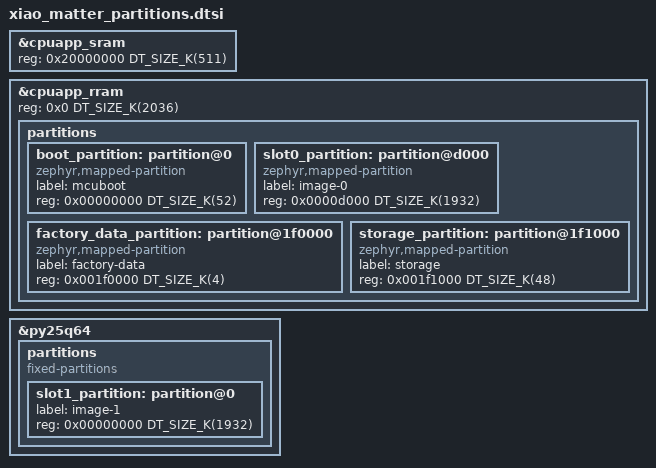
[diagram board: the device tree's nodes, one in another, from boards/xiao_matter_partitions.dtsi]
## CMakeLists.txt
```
#
# Copyright (c) 2021 Nordic Semiconductor ASA
#
# SPDX-License-Identifier: LicenseRef-Nordic-5-Clause
#

cmake_minimum_required(VERSION 3.20.0)

find_package(Zephyr HINTS $ENV{ZEPHYR_BASE})

project(thread-sound-detector)

# Enable GNU STD support.
include(${ZEPHYR_CONNECTEDHOMEIP_MODULE_DIR}/config/nrfconnect/app/enable-gnu-std.cmake)

# NORDIC SDK APP START

# Include all source files that are located in the Matter common directory.
include(${ZEPHYR_NRF_MODULE_DIR}/samples/matter/common/cmake/source_common.cmake)

# Include Data Model utils
include(${ZEPHYR_NRF_MODULE_DIR}/samples/matter/common/cmake/data_model.cmake)

include(${ZEPHYR_NRF_MODULE_DIR}/samples/matter/common/cmake/zap_helpers.cmake)
ncs_get_zap_parent_dir(ZAP_PARENT_DIR)

target_include_directories(app PRIVATE
  src
  ${ZAP_PARENT_DIR}
)

target_sources(app PRIVATE
  src/app_task.cpp
  src/main.cpp
  src/label_provider.cpp
  src/device_info.cpp
  src/audio.c
  src/dsp.c
  src/detector.c
)

if(CONFIG_TSD_MODEL_INT8)
  target_sources(app PRIVATE src/model_q8.c)
endif()

# Inference speed: the rest of the image is size-optimized
set_source_files_properties(src/dsp.c src/model_q8.c PROPERTIES COMPILE_OPTIONS "-O3")

ncs_configure_data_model()
# NORDIC SDK APP END
```

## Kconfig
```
#
# Copyright (c) 2022 Nordic Semiconductor
#
# SPDX-License-Identifier: LicenseRef-Nordic-5-Clause
#
mainmenu "Matter nRF Connect Template Example Application"

# Sample configuration used for Thread networking
if OPENTHREAD

choice OPENTHREAD_NORDIC_LIBRARY_CONFIGURATION
	default OPENTHREAD_NORDIC_LIBRARY_MTD
endchoice

choice OPENTHREAD_DEVICE_TYPE
	default OPENTHREAD_MTD
endchoice

# SED with 0 dBm Thread TX output power for nRF54L15 tag
if BOARD_NRF54L15TAG

config CHIP_ENABLE_ICD_SUPPORT
	default y

config OPENTHREAD_DEFAULT_TX_POWER
	default 0

endif

endif # OPENTHREAD

config CHIP_WIFI
	default y if SHIELD_NRF7002EB2

source "$(ZEPHYR_CONNECTEDHOMEIP_MODULE_DIR)/config/nrfconnect/chip-module/Kconfig.features"
source "$(ZEPHYR_CONNECTEDHOMEIP_MODULE_DIR)/config/nrfconnect/chip-module/Kconfig.defaults"
source "$(ZEPHYR_NRF_MODULE_DIR)/samples/matter/common/src/Kconfig"
config TSD_MODEL_INT8
	bool "Int8 sound model (CMSIS-NN)"
	select CMSIS_NN
	select CMSIS_NN_CONVOLUTION
	select CMSIS_NN_POOLING
	select CMSIS_NN_NNSUPPORT
	help
	  Run the int8 quantised model (model/quantize.py, model_data_q8.h)
	  with CMSIS-NN instead of the float model (model_data.h).

source "Kconfig.zephyr"
```

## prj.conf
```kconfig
#
# Copyright (c) 2021 Nordic Semiconductor ASA
#
# SPDX-License-Identifier: LicenseRef-Nordic-5-Clause
#

# This sample uses Kconfig.defaults to set options common for all
# samples. This file should contain only options specific for this sample
# or overrides of default values.

# Enable CHIP
CONFIG_CHIP=y
CONFIG_CHIP_PROJECT_CONFIG="src/chip_project_config.h"
CONFIG_CHIP_DEVICE_PRODUCT_NAME="Sound Detector"
CONFIG_CHIP_DEVICE_VENDOR_NAME="KinDR Software"

# Configure ZAP file name
CONFIG_NCS_SAMPLE_MATTER_ZAP_FILE_PATH="${APPLICATION_CONFIG_DIR}/src/default_zap/sound_detector.zap"

# 32768 == 0x8000: test product ID; together with test vendor 0xFFF1 Home Assistant
# names entities from the "ha_entitylabel" Fixed Label.
# (example Product ID added temporaly,
# but it must be changed with proper PID from the list:
# https://github.com/project-chip/connectedhomeip/blob/482e6fd03196a6de45465a90003947ef4b86e0b1/docs/examples/discussion/PID_allocation_for_example_apps.md)
CONFIG_CHIP_DEVICE_PRODUCT_ID=32768
CONFIG_STD_CPP17=y

# Enable Matter pairing automatically on application start.
CONFIG_CHIP_ENABLE_PAIRING_AUTOSTART=y

# Enable Matter extended announcement and increase duration to 1 hour.
CONFIG_CHIP_BLE_EXT_ADVERTISING=y
CONFIG_CHIP_BLE_ADVERTISING_DURATION=60

# Add support for LEDs and buttons on Nordic development kits
CONFIG_DK_LIBRARY=y

# Bluetooth Low Energy configuration
CONFIG_BT_DEVICE_NAME="SoundDetector"

# Other settings
CONFIG_THREAD_NAME=y
CONFIG_MPU_STACK_GUARD=y
CONFIG_RESET_ON_FATAL_ERROR=n
CONFIG_CHIP_LIB_SHELL=y
CONFIG_NCS_SAMPLE_MATTER_TEST_SHELL=y

# Disable NFC onboarding
CONFIG_CHIP_NFC_ONBOARDING_PAYLOAD=n

# Reduce application size
CONFIG_USE_SEGGER_RTT=n

# Enable Factory Data feature
CONFIG_CHIP_FACTORY_DATA=y
CONFIG_CHIP_FACTORY_DATA_BUILD=y

# ---- Sound detector ----
CONFIG_AUDIO=y
CONFIG_AUDIO_DMIC=y
CONFIG_FPU=y
CONFIG_CMSIS_DSP=y
CONFIG_CMSIS_DSP_TRANSFORM=y
CONFIG_SHELL=y

# snd selftest runs the CNN in the shell thread (CMSIS-NN needs more stack)
CONFIG_SHELL_STACK_SIZE=4096

# Logging off the hot path: minimal mode printed synchronously over UART in the
# calling thread, Matter debug bursts starved audio capture (PDM overruns ->
# restart transients -> false beep/smoke_alarm events -> more Matter traffic).
CONFIG_LOG_MODE_DEFERRED=y
CONFIG_LOG_BUFFER_SIZE=8192
CONFIG_MATTER_LOG_LEVEL_WRN=y
```

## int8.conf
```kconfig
# Int8 model variant: scripts/fw.sh build with MODEL=int8
CONFIG_TSD_MODEL_INT8=y
```

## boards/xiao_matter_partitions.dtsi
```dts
/*
 * Matter partition layout for XIAO nRF54LM20A, modelled on NCS
 * nrf/dts/samples/matter/nrf54lm20_cpuapp_partitions.dtsi, with the DFU
 * secondary slot in the on-board PY25Q64 external flash (Seeed wiki).
 */

&cpuapp_sram {
	reg = <0x20000000 DT_SIZE_K(511)>;
	ranges = <0x0 0x20000000 DT_SIZE_K(511)>;
};

&cpuapp_rram {
	reg = <0x0 DT_SIZE_K(2036)>;

	/delete-node/ partitions;

	partitions {
		ranges;
		#address-cells = <1>;
		#size-cells = <1>;

		boot_partition: partition@0 {
			compatible = "zephyr,mapped-partition";
			label = "mcuboot";
			reg = <0x00000000 DT_SIZE_K(52)>;
		};

		slot0_partition: partition@d000 {
			compatible = "zephyr,mapped-partition";
			label = "image-0";
			reg = <0x0000d000 DT_SIZE_K(1932)>;
		};

		factory_data_partition: partition@1f0000 {
			compatible = "zephyr,mapped-partition";
			label = "factory-data";
			reg = <0x001f0000 DT_SIZE_K(4)>;
		};

		storage_partition: partition@1f1000 {
			compatible = "zephyr,mapped-partition";
			label = "storage";
			reg = <0x001f1000 DT_SIZE_K(48)>;
		};
	};
};

&py25q64 {
	status = "okay";

	partitions {
		compatible = "fixed-partitions";
		#address-cells = <1>;
		#size-cells = <1>;

		slot1_partition: partition@0 {
			label = "image-1";
			reg = <0x00000000 DT_SIZE_K(1932)>;
		};
	};
};
```

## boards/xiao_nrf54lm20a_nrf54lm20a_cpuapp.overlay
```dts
#include "xiao_matter_partitions.dtsi"

/ {
	aliases {
		watchdog0 = &wdt31;
	};

	chosen {
		nordic,pm-ext-flash = &py25q64;
	};
};

&wdt31 {
	status = "okay";
};

/* Sense variant: PDM microphone, supply (PMIC LDO1) enabled at boot */
dmic_dev: &pdm20 {
	status = "okay";
};

/* As in Seeed's zephyr-dmic example */
&pwm20 {
	status = "disabled";
};
```

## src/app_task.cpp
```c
/*
 * Thread sound detector, Matter over Thread.
 *
 * Every sound class is a Generic Switch endpoint (1..N). A confirmed sound
 * event emits Switch InitialPress on that endpoint, which Home Assistant shows
 * as an event entity named after the class (Fixed Label "ha_entitylabel").
 *
 * Init structure based on the nRF Connect SDK Matter template sample,
 * Copyright (c) 2021 Nordic Semiconductor ASA
 * SPDX-License-Identifier: LicenseRef-Nordic-5-Clause
 */

#include "app_task.h"

#include "app/matter_init.h"
#include "app/task_executor.h"
#include "board/board.h"
#include "clusters/identify.h"
#include "lib/core/CHIPError.h"
#include "lib/support/CodeUtils.h"

#include <app/clusters/switch-server/switch-server.h>
#include <platform/CHIPDeviceLayer.h>
#include <setup_payload/OnboardingCodesUtil.h>

#include <zephyr/logging/log.h>
#include <zephyr/shell/shell.h>

#include <cstdlib>
#include <cstring>
#include <new>

#include "audio.h"
#include "detector.h"
#include "device_info.h"
#include "dsp.h"
#include "label_provider.h"

LOG_MODULE_DECLARE(app, CONFIG_CHIP_APP_LOG_LEVEL);

using namespace ::chip;
using namespace ::chip::app;
using namespace ::chip::DeviceLayer;

namespace {

SoundLabelProvider sLabelProvider;

/* Identify cluster on every sound endpoint (required by the Generic Switch device type). No LED or
 * sound to show, so identify requests are only logged. */
class LogIdentifyDelegate : public Clusters::IdentifyDelegate {
public:
	void OnIdentifyStart(Clusters::IdentifyCluster &) override { LOG_INF("Identify start"); }
	void OnIdentifyStop(Clusters::IdentifyCluster &) override { LOG_INF("Identify stop"); }
	void OnTriggerEffect(Clusters::IdentifyCluster &) override { LOG_INF("Identify trigger effect"); }
	bool IsTriggerEffectEnabled() const override { return false; }
};

LogIdentifyDelegate sIdentifyDelegate;
DefaultTimerDelegate sIdentifyTimer;
alignas(Nrf::Matter::IdentifyCluster) uint8_t sIdentifyStorage[MD_N_CLASSES][sizeof(Nrf::Matter::IdentifyCluster)];

CHIP_ERROR InitIdentify()
{
	for (int i = 0; i < MD_N_CLASSES; i++) {
		auto *cluster = new (sIdentifyStorage[i]) Nrf::Matter::IdentifyCluster(
			SoundLabelProvider::kFirstEndpoint + i, sIdentifyDelegate, sIdentifyTimer,
			Clusters::Identify::IdentifyTypeEnum::kNone);

		ReturnErrorOnFailure(cluster->Init());
	}
	return CHIP_NO_ERROR;
}

/* Runs on the Matter thread. */
void EmitSoundEvent(intptr_t cls)
{
	EndpointId ep = SoundLabelProvider::kFirstEndpoint + static_cast<EndpointId>(cls);

	Clusters::SwitchServer::Instance().OnInitialPress(ep, 1);
	LOG_INF("Matter event: %s on endpoint %u", SoundLabelProvider::PrettyName(cls), ep);
}

/* Called from the inference thread. */
void OnSoundEvent(int cls, float prob)
{
	ARG_UNUSED(prob);
	PlatformMgr().ScheduleWork(EmitSoundEvent, static_cast<intptr_t>(cls));
}

void OnAudioResult(const struct audio_result *res)
{
	detector_feed(res);
}

int CmdSelftest(const struct shell *sh, size_t argc, char **argv)
{
	int64_t t0 = k_uptime_get();
	float diff = dsp_selftest();

	shell_print(sh, "selftest: max |logit diff| vs Python = %.6f (%s), %lld ms", (double)diff,
		    diff < DSP_SELFTEST_TOL ? "PASS" : "FAIL", k_uptime_get() - t0);
	return 0;
}

int CmdVerbose(const struct shell *sh, size_t argc, char **argv)
{
	bool on = argv[1][0] == '1';

	detector_set_verbose(on);
	shell_print(sh, "verbose %d", on);
	return 0;
}

int CmdClasses(const struct shell *sh, size_t argc, char **argv)
{
	for (int i = 0; i < MD_N_CLASSES; i++) {
		shell_print(sh, "%2d endpoint %2d %-12s threshold %d%%", i,
			    SoundLabelProvider::kFirstEndpoint + i, md_class_names[i],
			    (int)(md_thresholds[i] * 100));
	}
	return 0;
}

/* Fire a Matter event without a sound, to test the Home Assistant side. */
int CmdTest(const struct shell *sh, size_t argc, char **argv)
{
	int cls = -1;

	for (int i = 0; i < MD_N_CLASSES; i++) {
		if (!strcmp(argv[1], md_class_names[i])) {
			cls = i;
		}
	}
	if (cls < 0) {
		char *end;
		long v = strtol(argv[1], &end, 10);

		if (*end == '\0' && v >= 0 && v < MD_N_CLASSES) {
			cls = (int)v;
		}
	}
	if (cls < 0) {
		shell_error(sh, "unknown class '%s' (see: snd classes)", argv[1]);
		return -EINVAL;
	}
	OnSoundEvent(cls, 1.0f);
	shell_print(sh, "test event %s queued", md_class_names[cls]);
	return 0;
}

SHELL_STATIC_SUBCMD_SET_CREATE(
	snd_cmds,
	SHELL_CMD(selftest, NULL, "Compare DSP+model output with the Python reference", CmdSelftest),
	SHELL_CMD_ARG(verbose, NULL, "verbose 0|1: log every classification", CmdVerbose, 2, 0),
	SHELL_CMD(classes, NULL, "List sound classes, endpoints and thresholds", CmdClasses),
	SHELL_CMD_ARG(test, NULL, "test <class|index>: emit a Matter event", CmdTest, 2, 0),
	SHELL_SUBCMD_SET_END);
SHELL_CMD_REGISTER(snd, &snd_cmds, "Sound detector", NULL);

} // namespace

CHIP_ERROR AppTask::Init()
{
	Nrf::Matter::InitData initData;

	initData.mDeviceInfoProvider = &sLabelProvider;
	ReturnErrorOnFailure(Nrf::Matter::PrepareServer(initData));

	if (!Nrf::GetBoard().Init()) {
		LOG_ERR("User interface initialization failed.");
		return CHIP_ERROR_INCORRECT_STATE;
	}
	ReturnErrorOnFailure(Nrf::Matter::RegisterEventHandler(Nrf::Board::DefaultMatterEventHandler, 0));
	ReturnErrorOnFailure(InitIdentify());
	ReturnErrorOnFailure(Nrf::Matter::StartServer());
	device_info_init();
	LOG_INF("%s %s, hardware %s", CONFIG_CHIP_DEVICE_PRODUCT_NAME, CHIP_DEVICE_CONFIG_DEVICE_SOFTWARE_VERSION_STRING,
		device_info_hw_string());

	float diff = dsp_selftest();

	LOG_INF("DSP selftest max diff %.6f %s", (double)diff, diff < DSP_SELFTEST_TOL ? "PASS" : "FAIL");
	detector_init(OnSoundEvent);
	audio_start(OnAudioResult);
	return CHIP_NO_ERROR;
}

CHIP_ERROR AppTask::StartApp()
{
	ReturnErrorOnFailure(Init());

	while (true) {
		Nrf::DispatchNextTask();
	}

	return CHIP_NO_ERROR;
}
```

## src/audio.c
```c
/*
 * PDM capture (16 kHz mono) -> log-mel frames (hop 20 ms) -> 1 s window
 * classified every 0.5 s in a separate lower-priority thread.
 */

#include <math.h>
#include <string.h>
#include <zephyr/kernel.h>
#include <zephyr/audio/dmic.h>
#include <zephyr/logging/log.h>
#include <hal/nrf_pdm.h>

#include "audio.h"
#include "dsp.h"

LOG_MODULE_REGISTER(audio, LOG_LEVEL_INF);

#define BLOCK_SAMPLES (MD_SR / 10) /* 100 ms */
#define BLOCK_BYTES   (BLOCK_SAMPLES * sizeof(int16_t))
#define BLOCK_COUNT   16 /* 1.6 s of slack when the CPU is busy */
#define SETTLE_BLOCKS 2  /* blocks dropped after a PDM (re)start: filter start-up transient */
#define READ_TIMEOUT  1000

#define INFER_EVERY_FRAMES (MD_N_FRAMES / 2) /* ~0.5 s */
#define LEVEL_BLOCKS 10                      /* 1 s of block energies */

K_MEM_SLAB_DEFINE_STATIC(pcm_slab, BLOCK_BYTES, BLOCK_COUNT, 4);

static audio_result_cb_t result_cb;

/* sample accumulator for framing */
static float pending[MD_WIN + BLOCK_SAMPLES + MD_HOP];
static size_t pending_len;

/* ring of log-mel frames */
static float mel_ring[MD_N_FRAMES][MD_N_MELS];
static size_t mel_head;
static size_t mel_count;
static size_t frames_since_infer;

static float block_ms[LEVEL_BLOCKS];
static size_t block_idx;

/* handed over to the inference thread */
static float infer_feat[MD_N_FRAMES * MD_N_MELS];
static float infer_level;
static K_SEM_DEFINE(infer_sem, 0, 1);
static atomic_t infer_busy;

static void queue_inference(void)
{
	if (atomic_get(&infer_busy)) {
		LOG_DBG("inference still running, window skipped");
		return;
	}
	for (size_t i = 0; i < MD_N_FRAMES; i++) {
		size_t src = (mel_head + i) % MD_N_FRAMES; /* oldest first */

		memcpy(&infer_feat[i * MD_N_MELS], mel_ring[src], sizeof(mel_ring[0]));
	}

	float ms = 0.0f;

	for (size_t i = 0; i < LEVEL_BLOCKS; i++) {
		ms += block_ms[i];
	}
	infer_level = 10.0f * log10f(ms / LEVEL_BLOCKS + 1e-12f);

	atomic_set(&infer_busy, 1);
	k_sem_give(&infer_sem);
}

static void process_block(const int16_t *pcm)
{
	float ms = 0.0f;

	for (size_t i = 0; i < BLOCK_SAMPLES; i++) {
		float v = pcm[i] / 32768.0f;

		pending[pending_len + i] = v;
		ms += v * v;
	}
	pending_len += BLOCK_SAMPLES;
	block_ms[block_idx] = ms / BLOCK_SAMPLES;
	block_idx = (block_idx + 1) % LEVEL_BLOCKS;

	size_t pos = 0;

	while (pending_len - pos >= MD_WIN) {
		dsp_logmel_frame(&pending[pos], mel_ring[mel_head]);
		mel_head = (mel_head + 1) % MD_N_FRAMES;
		if (mel_count < MD_N_FRAMES) {
			mel_count++;
		}
		pos += MD_HOP;

		if (++frames_since_infer >= INFER_EVERY_FRAMES && mel_count == MD_N_FRAMES) {
			frames_since_infer = 0;
			queue_inference();
		}
	}
	memmove(pending, &pending[pos], (pending_len - pos) * sizeof(float));
	pending_len -= pos;
}

static void capture_thread(void *a, void *b, void *c)
{
	const struct device *dmic = DEVICE_DT_GET(DT_NODELABEL(dmic_dev));
	struct pcm_stream_cfg stream = {
		.pcm_width = 16,
		.mem_slab = &pcm_slab,
		.pcm_rate = MD_SR,
		.block_size = BLOCK_BYTES,
	};
	struct dmic_cfg cfg = {
		.io = {
			.min_pdm_clk_freq = 1000000,
			.max_pdm_clk_freq = 3500000,
			.min_pdm_clk_dc = 40,
			.max_pdm_clk_dc = 60,
		},
		.streams = &stream,
		.channel = {
			.req_num_streams = 1,
			.req_num_chan = 1,
		},
	};
	int ret;

	cfg.channel.req_chan_map_lo = dmic_build_channel_map(0, 0, PDM_CHAN_LEFT);

	if (!device_is_ready(dmic)) {
		LOG_ERR("PDM device not ready");
		return;
	}
	ret = dmic_configure(dmic, &cfg);
	if (ret == 0) {
		/* Driver keeps the default 0 dB; MEMS mic level is low, use +20 dB */
		nrf_pdm_gain_set(NRF_PDM20, NRF_PDM_GAIN_MAXIMUM, NRF_PDM_GAIN_MAXIMUM);
		ret = dmic_trigger(dmic, DMIC_TRIGGER_START);
	}
	if (ret) {
		LOG_ERR("PDM start failed (%d)", ret);
		return;
	}
	LOG_INF("PDM capture %d Hz", MD_SR);
	int settle = SETTLE_BLOCKS;

	for (;;) {
		void *buf;
		uint32_t size;

		ret = dmic_read(dmic, 0, &buf, &size, READ_TIMEOUT);
		if (ret) {
			LOG_ERR("PDM read failed (%d), restarting", ret);
			dmic_trigger(dmic, DMIC_TRIGGER_STOP);
			k_msleep(100);
			dmic_trigger(dmic, DMIC_TRIGGER_START);
			/* Start over: the gap and the start-up transient must not reach the
			 * model (they looked like beeps). Inference resumes once 1 s of
			 * new audio has filled the mel ring. */
			pending_len = 0;
			mel_count = 0;
			frames_since_infer = 0;
			settle = SETTLE_BLOCKS;
			continue;
		}
		if (size == BLOCK_BYTES && settle > 0) {
			settle--;
		} else if (size == BLOCK_BYTES) {
			process_block(buf);
		}
		k_mem_slab_free(&pcm_slab, buf);
	}
}

static void infer_thread(void *a, void *b, void *c)
{
	for (;;) {
		struct audio_result res;
		float logits[MD_N_CLASSES];

		k_sem_take(&infer_sem, K_FOREVER);
		int64_t t0 = k_uptime_get();

		dsp_model_run(infer_feat, logits);
		res.infer_ms = (uint32_t)(k_uptime_get() - t0);
		res.level_dbfs = infer_level;

		/* multi-label: independent sigmoid per class */
		for (int i = 0; i < MD_N_CLASSES; i++) {
			res.prob[i] = 1.0f / (1.0f + expf(-logits[i]));
		}
		atomic_set(&infer_busy, 0);

		if (result_cb) {
			result_cb(&res);
		}
	}
}

/* Capture above the Matter/OpenThread threads (priority 8 and lower): it only
 * needs a few ms per 100 ms block, but must never fall behind the PDM DMA. */
K_THREAD_DEFINE(capture_tid, 4096, capture_thread, NULL, NULL, NULL, 2, 0, K_TICKS_FOREVER);
K_THREAD_DEFINE(infer_tid, 4096, infer_thread, NULL, NULL, NULL, 10, 0, K_TICKS_FOREVER);

int audio_start(audio_result_cb_t cb)
{
	result_cb = cb;
	k_thread_start(infer_tid);
	k_thread_start(capture_tid);
	return 0;
}
```

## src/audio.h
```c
#ifndef TSD_AUDIO_H
#define TSD_AUDIO_H

#include <stdint.h>
#include "model.h"

#ifdef __cplusplus
extern "C" {
#endif

struct audio_result {
	float prob[MD_N_CLASSES];
	float level_dbfs; /* RMS level of the classified 1 s window */
	uint32_t infer_ms;
};

typedef void (*audio_result_cb_t)(const struct audio_result *res);

/* Starts PDM capture, feature extraction and periodic classification. */
int audio_start(audio_result_cb_t cb);

#ifdef __cplusplus
}
#endif

#endif
```

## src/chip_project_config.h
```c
/*
 * Copyright (c) 2021 Nordic Semiconductor ASA
 *
 * SPDX-License-Identifier: LicenseRef-Nordic-5-Clause
 */

/**
 *    @file
 *          Example project configuration file for CHIP.
 *
 *          This is a place to put application or project-specific overrides
 *          to the default configuration values for general CHIP features.
 *
 */

#pragma once

/* Basic Information SoftwareVersionString "1.0.0" from firmware/VERSION; NCS default is
 * APP_VERSION_EXTENDED_STRING ("1.0.0+0"). scripts/fw.sh sets the same string in matter.ota. */
#include <app_version.h>
#define CONFIG_CHIP_DEVICE_SOFTWARE_VERSION_STRING APP_VERSION_STRING
```

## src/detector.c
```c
/*
 * Turns per-window class probabilities into discrete sound events:
 * - class probability >= per-class threshold (exported with the model)
 * - in md_confirm[class] consecutive windows (1 or 2, exported with the model;
 *   windows overlap by 0.5 s)
 * - input level above LEVEL_GATE_DBFS (mic noise floor is ~ -70 dBFS with +20 dB PDM gain)
 * - at most one event per class every COOLDOWN_MS
 * - alarm family: a generic class (alarm, beep) does not fire while a specific
 *   one (smoke_alarm, alarm_clock, phone_ring) is above its threshold or fired
 *   within COOLDOWN_MS; a smoke alarm is also an alarm and a beep, one event is
 *   enough (validation: generic+specific false events -16 %, specific classes
 *   and family-level recall unchanged)
 */

#include <string.h>
#include <zephyr/kernel.h>
#include <zephyr/logging/log.h>

#include "detector.h"

LOG_MODULE_REGISTER(detector, LOG_LEVEL_INF);

#define LEVEL_GATE_DBFS (-64.0f)
#define COOLDOWN_MS 5000

static detector_event_cb_t event_cb;
static bool verbose;
static uint8_t hits[MD_N_CLASSES];
static int64_t last_event[MD_N_CLASSES];
static int64_t last_specific;

static const char *const specific_names[] = {"smoke_alarm", "alarm_clock", "phone_ring"};
static const char *const generic_names[] = {"alarm", "beep"};
static bool is_specific[MD_N_CLASSES];
static bool is_generic[MD_N_CLASSES];

static void mark(const char *const *names, size_t n, bool *flags)
{
	for (size_t i = 0; i < n; i++) {
		for (int c = 0; c < MD_N_CLASSES; c++) {
			if (strcmp(md_class_names[c], names[i]) == 0) {
				flags[c] = true;
			}
		}
	}
}

void detector_init(detector_event_cb_t cb)
{
	event_cb = cb;
	for (int i = 0; i < MD_N_CLASSES; i++) {
		last_event[i] = -COOLDOWN_MS;
	}
	last_specific = -COOLDOWN_MS;
	mark(specific_names, ARRAY_SIZE(specific_names), is_specific);
	mark(generic_names, ARRAY_SIZE(generic_names), is_generic);
}

void detector_set_verbose(bool on)
{
	verbose = on;
}

void detector_feed(const struct audio_result *res)
{
	const bool loud = res->level_dbfs >= LEVEL_GATE_DBFS;
	const int64_t now = k_uptime_get();
	int best = 0;
	bool specific_active = now - last_specific < COOLDOWN_MS;

	for (int c = 0; c < MD_N_CLASSES; c++) {
		if (is_specific[c] && loud && res->prob[c] >= md_thresholds[c]) {
			specific_active = true;
		}
	}

	for (int c = 0; c < MD_N_CLASSES; c++) {
		if (res->prob[c] > res->prob[best]) {
			best = c;
		}
		if (!loud || res->prob[c] < md_thresholds[c]) {
			hits[c] = 0;
			continue;
		}
		if (hits[c] < md_confirm[c]) {
			hits[c]++;
		}
		if (hits[c] == md_confirm[c] && now - last_event[c] >= COOLDOWN_MS &&
		    !(is_generic[c] && specific_active)) {
			last_event[c] = now;
			if (is_specific[c]) {
				last_specific = now;
			}
			LOG_INF("EVENT %s p=%d%% level %d dBFS", md_class_names[c],
				(int)(res->prob[c] * 100), (int)res->level_dbfs);
			if (event_cb) {
				event_cb(c, res->prob[c]);
			}
		}
	}

	if (verbose) {
		LOG_INF("top %-12s %3d%% (thr %d%%) level %d dBFS infer %u ms",
			md_class_names[best], (int)(res->prob[best] * 100),
			(int)(md_thresholds[best] * 100), (int)res->level_dbfs, res->infer_ms);
	}
}
```

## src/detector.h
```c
#ifndef TSD_DETECTOR_H
#define TSD_DETECTOR_H

#include <stdbool.h>
#include "audio.h"

#ifdef __cplusplus
extern "C" {
#endif

/* Called (from the inference thread) when a sound event is confirmed. */
typedef void (*detector_event_cb_t)(int cls, float prob);

void detector_init(detector_event_cb_t cb);

/* Feed one classification result (every ~0.5 s). */
void detector_feed(const struct audio_result *res);

void detector_set_verbose(bool on);

#ifdef __cplusplus
}
#endif

#endif
```

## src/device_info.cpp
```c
/*
 * Basic Information overrides on top of the factory data provider:
 * - VendorName from Kconfig (factory data only changes with a USB flash, OTA keeps it)
 * - HardwareVersionString: board name + SoC part and variant (silicon revision) from FICR
 * - SerialNumber: the chip's unique FICR DEVICEID instead of the shared default
 * Everything else (VID/PID, attestation, onboarding) comes from the factory data.
 */

#include "device_info.h"

#include <cstdio>
#include <cstring>

#include <hal/nrf_ficr.h>
#include <platform/DeviceInstanceInfoProvider.h>
#include <platform/PlatformManager.h>

using namespace chip;
using namespace chip::DeviceLayer;

namespace {

#define BOARD_NAME "Seeed XIAO nRF54LM20A Sense"

CHIP_ERROR CopyString(const char *src, char *buf, size_t bufSize)
{
	size_t len = strlen(src);

	VerifyOrReturnError(len < bufSize, CHIP_ERROR_BUFFER_TOO_SMALL);
	memcpy(buf, src, len + 1);
	return CHIP_NO_ERROR;
}

/* "nRF54LM20A AAB0": part from FICR INFO.PART, variant (silicon revision) from INFO.VARIANT. */
void SocString(char *buf, size_t bufSize)
{
	uint32_t part = NRF_FICR->INFO.PART;
	uint32_t variant = NRF_FICR->INFO.VARIANT;
	char var[5];

	for (int i = 0; i < 4; i++) {
		char ch = (char)(variant >> (24 - 8 * i));

		var[i] = (ch >= 0x20 && ch < 0x7f) ? ch : '?';
	}
	var[4] = '\0';
	switch (part) {
	case FICR_INFO_PART_PART_N54LM20A:
		snprintf(buf, bufSize, "nRF54LM20A %s", var);
		break;
	case FICR_INFO_PART_PART_N54LM20B:
		snprintf(buf, bufSize, "nRF54LM20B %s", var);
		break;
	default:
		snprintf(buf, bufSize, "part %08X %s", (unsigned)part, var);
		break;
	}
}

class InfoProvider : public DeviceInstanceInfoProvider {
public:
	void SetBase(DeviceInstanceInfoProvider *base) { mBase = base; }

	CHIP_ERROR GetVendorName(char *buf, size_t bufSize) override
	{
		return CopyString(CONFIG_CHIP_DEVICE_VENDOR_NAME, buf, bufSize);
	}
	CHIP_ERROR GetVendorId(uint16_t &v) override { return mBase->GetVendorId(v); }
	CHIP_ERROR GetProductName(char *buf, size_t n) override { return mBase->GetProductName(buf, n); }
	CHIP_ERROR GetProductId(uint16_t &v) override { return mBase->GetProductId(v); }
	CHIP_ERROR GetPartNumber(char *buf, size_t n) override { return mBase->GetPartNumber(buf, n); }
	CHIP_ERROR GetProductURL(char *buf, size_t n) override { return mBase->GetProductURL(buf, n); }
	CHIP_ERROR GetProductLabel(char *buf, size_t n) override { return mBase->GetProductLabel(buf, n); }
	CHIP_ERROR GetManufacturingDate(uint16_t &y, uint8_t &m, uint8_t &d) override
	{
		return mBase->GetManufacturingDate(y, m, d);
	}
	CHIP_ERROR GetHardwareVersion(uint16_t &v) override { return mBase->GetHardwareVersion(v); }
	CHIP_ERROR GetRotatingDeviceIdUniqueId(MutableByteSpan &span) override
	{
		return mBase->GetRotatingDeviceIdUniqueId(span);
	}

	CHIP_ERROR GetHardwareVersionString(char *buf, size_t bufSize) override
	{
		return CopyString(device_info_hw_string(), buf, bufSize);
	}

	CHIP_ERROR GetSerialNumber(char *buf, size_t bufSize) override
	{
		VerifyOrReturnError(bufSize > 16, CHIP_ERROR_BUFFER_TOO_SMALL);
		snprintf(buf, bufSize, "%08X%08X", (unsigned)NRF_FICR->INFO.DEVICEID[1],
			 (unsigned)NRF_FICR->INFO.DEVICEID[0]);
		return CHIP_NO_ERROR;
	}

private:
	DeviceInstanceInfoProvider *mBase = nullptr;
};

InfoProvider sProvider;

} // namespace

const char *device_info_hw_string()
{
	static char str[65];

	if (!str[0]) {
		char soc[32];

		SocString(soc, sizeof(soc));
		snprintf(str, sizeof(str), "%s, %s", BOARD_NAME, soc);
	}
	return str;
}

void device_info_init()
{
	DeviceInstanceInfoProvider *base = GetDeviceInstanceInfoProvider();

	if (base == nullptr || base == &sProvider) {
		return;
	}
	sProvider.SetBase(base);
	PlatformMgr().LockChipStack();
	SetDeviceInstanceInfoProvider(&sProvider);
	PlatformMgr().UnlockChipStack();
}
```

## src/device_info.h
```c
#pragma once

/* Basic Information overrides (vendor name, hardware string, serial number), see device_info.cpp. */

/* Install the provider; call after Nrf::Matter::StartServer(). */
void device_info_init();

/* "Seeed XIAO nRF54LM20A Sense, nRF54LM20A AAB0" (board, SoC part and variant). */
const char *device_info_hw_string();
```

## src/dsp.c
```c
/*
 * Log-mel features and student CNN inference, mirrors model/features.py and
 * model/train_student.py:
 *   Hann(WIN) -> zero pad N_FFT -> |rfft|^2 -> mel filterbank -> ln(x + eps)
 *   normalize -> conv3x3 + ReLU + maxpool2
 *   -> blocks [dw3x3 + ReLU -> pw1x1 + ReLU (-> maxpool2)] -> GAP -> FC
 * Float model: tensors CHW, weights in PyTorch layout with BatchNorm folded.
 * Int8 model (CONFIG_TSD_MODEL_INT8): model_q8.c.
 */

#include <math.h>
#include <string.h>
#include <stdbool.h>
#include <zephyr/kernel.h>
#include <zephyr/sys/util.h>
#include <arm_math.h>

#include "dsp.h"

#define N_BINS (MD_N_FFT / 2 + 1)
#define H0 MD_N_FRAMES
#define W0 MD_N_MELS

/* Static work buffers: FFT ones (fft_lock) and CNN ones (model_lock). */
static K_MUTEX_DEFINE(fft_lock);
static K_MUTEX_DEFINE(model_lock);

static float window[MD_WIN];
static bool window_ready;
static arm_rfft_fast_instance_f32 rfft;
static float fft_in[MD_N_FFT];
static float fft_out[MD_N_FFT];
static float power[N_BINS];

static void dsp_init(void)
{
	for (int i = 0; i < MD_WIN; i++) {
		window[i] = 0.5f - 0.5f * cosf(2.0f * (float)PI * i / MD_WIN);
	}
	arm_rfft_fast_init_f32(&rfft, MD_N_FFT);
	window_ready = true;
}

static void logmel_frame(const float *samples, float *mel_out)
{
	if (!window_ready) {
		dsp_init();
	}
	for (int i = 0; i < MD_WIN; i++) {
		fft_in[i] = samples[i] * window[i];
	}
	memset(&fft_in[MD_WIN], 0, (MD_N_FFT - MD_WIN) * sizeof(float));

	arm_rfft_fast_f32(&rfft, fft_in, fft_out, 0);

	/* CMSIS packed format: [re0, re(N/2), re1, im1, re2, im2, ...] */
	power[0] = fft_out[0] * fft_out[0];
	power[N_BINS - 1] = fft_out[1] * fft_out[1];
	for (int k = 1; k < N_BINS - 1; k++) {
		float re = fft_out[2 * k];
		float im = fft_out[2 * k + 1];

		power[k] = re * re + im * im;
	}
	for (int m = 0; m < MD_N_MELS; m++) {
		const float *fb = &md_mel_fb[m * N_BINS];
		float acc = 0.0f;

		for (int k = 0; k < N_BINS; k++) {
			acc += fb[k] * power[k];
		}
		mel_out[m] = logf(acc + MD_LOG_EPS);
	}
}

#ifndef CONFIG_TSD_MODEL_INT8
/* three rotating activation buffers: block input, depthwise output, block output */
static float buf[3][MD_MAX_ACT];
static float padded[(H0 + 2) * (W0 + 2)];
static float plane[H0 * W0];

/* 3x3 convolution of one zero-padded input plane, accumulated into plane[]. */
static void conv_plane_acc(const float *src_padded, int h, int w, const float *k)
{
	const int pw = w + 2;

	for (int ky = 0; ky < 3; ky++) {
		for (int kx = 0; kx < 3; kx++) {
			const float kv = k[ky * 3 + kx];

			for (int y = 0; y < h; y++) {
				const float *s = &src_padded[(y + ky) * pw + kx];
				float *d = &plane[y * w];

				for (int x = 0; x < w; x++) {
					d[x] += kv * s[x];
				}
			}
		}
	}
}

static void pad_plane(const float *in, int h, int w)
{
	const int pw = w + 2;

	memset(padded, 0, (h + 2) * pw * sizeof(float));
	for (int y = 0; y < h; y++) {
		memcpy(&padded[(y + 1) * pw + 1], &in[y * w], w * sizeof(float));
	}
}

/* ReLU and optional 2x2 max pooling (floor) of plane[] into out. */
static void relu_pool_store(int h, int w, bool pool, float *out)
{
	if (!pool) {
		for (int i = 0; i < h * w; i++) {
			out[i] = MAX(plane[i], 0.0f);
		}
		return;
	}
	const int oh = h / 2, ow = w / 2;

	for (int oy = 0; oy < oh; oy++) {
		for (int ox = 0; ox < ow; ox++) {
			const float *p = &plane[(2 * oy) * w + 2 * ox];
			float m = MAX(MAX(p[0], p[1]), MAX(p[w], p[w + 1]));

			out[oy * ow + ox] = MAX(m, 0.0f);
		}
	}
}

/* Input conv: 1 -> MD_C0 channels, ReLU, maxpool. */
static void conv0(const float *in, float *out)
{
	pad_plane(in, H0, W0);
	for (int co = 0; co < MD_C0; co++) {
		for (int i = 0; i < H0 * W0; i++) {
			plane[i] = md_c0_b[co];
		}
		conv_plane_acc(padded, H0, W0, &md_c0_w[co * 9]);
		relu_pool_store(H0, W0, true, &out[co * (H0 / 2) * (W0 / 2)]);
	}
}

/* Depthwise 3x3 + ReLU (in -> tmp), pointwise 1x1 + ReLU (+pool) (tmp -> out). */
static void ds_block(const struct md_block *b, const float *in, float *tmp, float *out, int h,
		     int w)
{
	const int hw = h * w;

	for (int c = 0; c < b->cin; c++) {
		pad_plane(&in[c * hw], h, w);
		for (int i = 0; i < hw; i++) {
			plane[i] = b->dw_b[c];
		}
		conv_plane_acc(padded, h, w, &b->dw_w[c * 9]);
		relu_pool_store(h, w, false, &tmp[c * hw]);
	}

	const int ohw = b->pool ? (h / 2) * (w / 2) : hw;

	for (int co = 0; co < b->cout; co++) {
		const float *wt = &b->pw_w[co * b->cin];

		for (int i = 0; i < hw; i++) {
			plane[i] = b->pw_b[co];
		}
		for (int ci = 0; ci < b->cin; ci++) {
			const float kv = wt[ci];
			const float *s = &tmp[ci * hw];

			for (int i = 0; i < hw; i++) {
				plane[i] += kv * s[i];
			}
		}
		relu_pool_store(h, w, b->pool, &out[co * ohw]);
	}
}

static void model_run(const float *feat, float *logits)
{
	int h = H0 / 2, w = W0 / 2;
	float *in = buf[0], *tmp = buf[1], *out = buf[2];

	/* normalized input in buf[1], conv0 output in buf[0] */
	for (int i = 0; i < H0 * W0; i++) {
		tmp[i] = (feat[i] - MD_NORM_MEAN) / MD_NORM_STD;
	}
	conv0(tmp, in);

	for (int i = 0; i < MD_N_BLOCKS; i++) {
		const struct md_block *b = &md_blocks[i];
		float *t;

		ds_block(b, in, tmp, out, h, w);
		t = in;
		in = out;
		out = tmp;
		tmp = t;
		if (b->pool) {
			h /= 2;
			w /= 2;
		}
	}
	const float *cur = in;

	float gap[MD_C_LAST];

	for (int c = 0; c < MD_C_LAST; c++) {
		float s = 0.0f;

		for (int i = 0; i < h * w; i++) {
			s += cur[c * h * w + i];
		}
		gap[c] = s / (h * w);
	}
	for (int o = 0; o < MD_N_CLASSES; o++) {
		float s = md_fc_b[o];

		for (int c = 0; c < MD_C_LAST; c++) {
			s += md_fc_w[o * MD_C_LAST + c] * gap[c];
		}
		logits[o] = s;
	}
}
#endif /* !CONFIG_TSD_MODEL_INT8 */

void dsp_logmel_frame(const float *samples, float *mel_out)
{
	k_mutex_lock(&fft_lock, K_FOREVER);
	logmel_frame(samples, mel_out);
	k_mutex_unlock(&fft_lock);
}

void dsp_model_run(const float *feat, float *logits)
{
	k_mutex_lock(&model_lock, K_FOREVER);
#ifdef CONFIG_TSD_MODEL_INT8
	model_q8_run(feat, logits);
#else
	model_run(feat, logits);
#endif
	k_mutex_unlock(&model_lock);
}

float dsp_selftest(void)
{
	/* Same chirp as model/features.py test_signal(), generated frame by frame */
	static float frame[MD_WIN];
	static float feat[MD_N_FRAMES * MD_N_MELS];
	const int n = MD_WIN + MD_HOP * (MD_N_FRAMES - 1);
	const double f0 = 300.0, f1 = 4000.0;
	const double k = (f1 - f0) / ((double)n / MD_SR);
	float logits[MD_N_CLASSES];
	float max_diff = 0.0f;

	for (int f = 0; f < MD_N_FRAMES; f++) {
		for (int i = 0; i < MD_WIN; i++) {
			double t = (double)(f * MD_HOP + i) / MD_SR;

			frame[i] = (float)(0.3 * sin(2.0 * 3.14159265358979323846 *
						     (f0 * t + 0.5 * k * t * t)));
		}
		dsp_logmel_frame(frame, &feat[f * MD_N_MELS]);
	}
	dsp_model_run(feat, logits);
	for (int i = 0; i < MD_N_CLASSES; i++) {
		max_diff = MAX(max_diff, fabsf(logits[i] - md_test_logits[i]));
	}
	return max_diff;
}
```

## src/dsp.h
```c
#ifndef TSD_DSP_H
#define TSD_DSP_H

#include "model.h"

#ifdef __cplusplus
extern "C" {
#endif

/* One log-mel frame from MD_WIN samples (float, [-1, 1]). Matches model/train.py logmel(). */
void dsp_logmel_frame(const float *samples, float *mel_out);

/* Run the CNN on [MD_N_FRAMES][MD_N_MELS] log-mel features. */
void dsp_model_run(const float *feat, float *logits);

/* Int8 CNN (model_q8.c), called by dsp_model_run() with the model lock held. */
void model_q8_run(const float *feat, float *logits);

/* Compare firmware output with the Python reference; returns max abs logit diff.
 * Int8: the float front end may flip a rare input rounding, hence the looser limit. */
#ifdef CONFIG_TSD_MODEL_INT8
#define DSP_SELFTEST_TOL 5e-2f
#else
#define DSP_SELFTEST_TOL 1e-2f
#endif
float dsp_selftest(void);

#ifdef __cplusplus
}
#endif

#endif
```

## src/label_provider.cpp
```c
#include "label_provider.h"

#include <cctype>
#include <cstring>

#include <lib/support/CHIPMemString.h>
#include <platform/CHIPDeviceLayer.h>

#include "model.h"

using namespace chip;

namespace {

constexpr char kLabelKey[] = "ha_entitylabel";
char sPretty[MD_N_CLASSES][DeviceLayer::kMaxLabelValueLength + 1];

class SingleLabelIterator : public DeviceLayer::DeviceInfoProvider::FixedLabelIterator {
public:
	explicit SingleLabelIterator(const char *value) : mValue(value) {}
	size_t Count() override { return 1; }
	bool Next(DeviceLayer::DeviceInfoProvider::FixedLabelType &output) override
	{
		if (mDone) {
			return false;
		}
		output.label = CharSpan::fromCharString(kLabelKey);
		output.value = CharSpan::fromCharString(mValue);
		mDone = true;
		return true;
	}
	void Release() override { Platform::Delete(this); }

private:
	const char *mValue;
	bool mDone = false;
};

} // namespace

const char *SoundLabelProvider::PrettyName(int cls)
{
	if (cls < 0 || cls >= MD_N_CLASSES) {
		return "";
	}
	char *out = sPretty[cls];

	if (out[0] == '\0') {
		/* "dog_bark" -> "Dog bark" */
		Platform::CopyString(out, sizeof(sPretty[cls]), md_class_names[cls]);
		for (char *p = out; *p; p++) {
			if (*p == '_') {
				*p = ' ';
			}
		}
		out[0] = static_cast<char>(toupper(out[0]));
	}
	return out;
}

DeviceLayer::DeviceInfoProvider::FixedLabelIterator *SoundLabelProvider::IterateFixedLabel(EndpointId endpoint)
{
	if (endpoint < kFirstEndpoint || endpoint >= kFirstEndpoint + MD_N_CLASSES) {
		return nullptr;
	}
	return Platform::New<SingleLabelIterator>(PrettyName(endpoint - kFirstEndpoint));
}
```

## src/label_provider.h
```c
#pragma once

#include <DeviceInfoProviderImpl.h>

/*
 * Fixed Label per sound endpoint: {"ha_entitylabel": "<Class name>"}.
 * Home Assistant uses this label to name Matter entities of test/DIY devices
 * (vendor 0xFFF1, product 0x8000..0x8002).
 */
class SoundLabelProvider : public chip::DeviceLayer::DeviceInfoProviderImpl {
public:
	FixedLabelIterator *IterateFixedLabel(chip::EndpointId endpoint) override;

	/* Endpoint of the first sound class; class i lives on kFirstEndpoint + i. */
	static constexpr chip::EndpointId kFirstEndpoint = 1;

	static const char *PrettyName(int cls);
};
```
